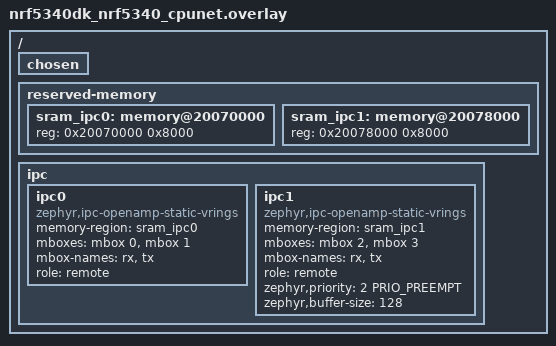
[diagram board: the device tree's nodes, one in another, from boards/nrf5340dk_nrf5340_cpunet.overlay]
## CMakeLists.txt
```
# Copyright 2026 NXP
# SPDX-License-Identifier: Apache-2.0

cmake_minimum_required(VERSION 3.20.0)

find_package(Zephyr REQUIRED HINTS $ENV{ZEPHYR_BASE})
project(mp_ipc_multi_core_remote)

target_sources(app PRIVATE src/main.c src/mp_test_sink.c)
target_sources_ifdef(CONFIG_MBOX app PRIVATE src/mbox_mock.c)
```

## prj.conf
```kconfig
# Copyright 2026 NXP
# SPDX-License-Identifier: Apache-2.0

CONFIG_MP=y
CONFIG_IPC_SERVICE=y
CONFIG_MP_PLUGIN_IPC=y

# IPC Service Backend Config
CONFIG_MBOX=y
CONFIG_OPENAMP=y
CONFIG_IPC_SERVICE_BACKEND_RPMSG=y
CONFIG_IPM=y
CONFIG_IPM_MHU=y

# Disable cache management for QEMU emulation to avoid arch-specific linker issues
CONFIG_CACHE_MANAGEMENT=n

# MediaPipe Subsystem Config
CONFIG_MP_THREADS_NUM=2
CONFIG_MP_NET_BUF_POOL_COUNT=8

# Logging Configuration
CONFIG_LOG=y
CONFIG_LOG_DEFAULT_LEVEL=3
CONFIG_MP_LOG_LEVEL_DBG=y
CONFIG_PRINTK=y

# Heap and buffer allocations
CONFIG_HEAP_MEM_POOL_SIZE=16384
CONFIG_NET_BUF=y
```

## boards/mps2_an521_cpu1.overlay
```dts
/*
 * Copyright 2026 NXP
 *
 * SPDX-License-Identifier: Apache-2.0
 */

/ {
	chosen {
		zephyr,ipc_shm = &sramx;
		zephyr,ipc = &mhu0;
	};

	sramx: memory@281f8000 {
		compatible = "mmio-sram";
		reg = <0x281f8000 0x8000>;
	};

	mbox_mock: mbox_mock {
		compatible = "zephyr,mbox-mock";
		#mbox-cells = <0>;
		status = "okay";
	};

	ipc0: ipc0 {
		compatible = "zephyr,ipc-openamp-static-vrings";
		memory-region = <&sramx>;
		mboxes = <&mbox_mock>, <&mbox_mock>;
		mbox-names = "tx", "rx";
		role = "remote";
		status = "okay";
	};
};
```

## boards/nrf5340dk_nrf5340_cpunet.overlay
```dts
/*
 * Copyright (c) 2021 Carlo Caione <ccaione@baylibre.com>
 *
 * SPDX-License-Identifier: Apache-2.0
 */

#include <zephyr/dt-bindings/ipc_service/static_vrings.h>

/delete-node/ &sram0_shared;

/ {
	chosen {
		/delete-property/ zephyr,ipc_shm;
	};

	reserved-memory {
		#address-cells = <1>;
		#size-cells = <1>;

		sram_ipc0: memory@20070000 {
			reg = <0x20070000 0x8000>;
		};

		sram_ipc1: memory@20078000 {
			reg = <0x20078000 0x8000>;
		};
	};

	ipc {
		/delete-node/ ipc0;

		ipc0: ipc0 {
			compatible = "zephyr,ipc-openamp-static-vrings";
			memory-region = <&sram_ipc0>;
			mboxes = <&mbox 0>, <&mbox 1>;
			mbox-names = "rx", "tx";
			role = "remote";
			status = "okay";
		};

		ipc1: ipc1 {
			compatible = "zephyr,ipc-openamp-static-vrings";
			memory-region = <&sram_ipc1>;
			mboxes = <&mbox 2>, <&mbox 3>;
			mbox-names = "rx", "tx";
			role = "remote";
			zephyr,priority = <2 PRIO_PREEMPT>;
			zephyr,buffer-size = <128>;
			status = "okay";
		};
	};
};
```

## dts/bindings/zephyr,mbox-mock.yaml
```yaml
description: Mock MBOX-to-IPM Shim

compatible: "zephyr,mbox-mock"

include: base.yaml

properties:
  "#mbox-cells":
    type: int
    const: 0
```

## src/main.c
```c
/*
 * Copyright (c) 2026 Qualcomm Innovation Center, Inc. All rights reserved.
 *
 * SPDX-License-Identifier: Apache-2.0
 */

#include <zephyr/kernel.h>
#include <zephyr/logging/log.h>
#include <zephyr/net_buf.h>

#include <zephyr/mp/core/mp.h>
#include <zephyr/mp/core/mp_pipeline.h>
#include <zephyr/mp/core/mp_bin.h>
#include <zephyr/mp/core/mp_element.h>
#include <zephyr/mp/core/mp_pad.h>
#include <zephyr/mp/ipc/mp_ipc.h>
#include <zephyr/mp/ipc/mp_ipc_protocol.h>

#include "mp_test_sink.h"

LOG_MODULE_REGISTER(mp_ipc_remote_app, LOG_LEVEL_INF);

#define PIPE_B_ID    0
#define IPC_SRC_ID   1
#define TEST_SINK_ID 2

static struct mp_pipeline pipeline_b;
static struct mp_ipc_src ipc_src;
static struct mp_test_sink test_sink;

/* Semaphore to signal from app_create_remote_pipeline() to main() */
K_SEM_DEFINE(pipeline_created_sem, 0, 1);

/* Application hook called from mp_ipc_src.c when CPU0 sends CREATE_PIPELINE */
int app_create_remote_pipeline(void)
{
	int ret;

	LOG_INF("[CPU1] Creating remote pipeline");

	/* Build the pipeline and elements */
	MP_ELEMENT_INIT(&pipeline_b, mp_pipeline_init, PIPE_B_ID);
	MP_ELEMENT_INIT(&test_sink, mp_test_sink_init, TEST_SINK_ID);

	ret = mp_element_link((struct mp_element *)&ipc_src, (struct mp_element *)&test_sink, NULL);
	if (ret < 0) {
		LOG_ERR("Failed to link ipc_src to test_sink (%d)", ret);
		return ret;
	}
	LOG_INF("[CPU1] Elements linked successfully.");

	ret = mp_bin_add((struct mp_bin *)&pipeline_b,
			 (struct mp_element *)&ipc_src,
			 (struct mp_element *)&test_sink,
			 NULL);
	if (ret < 0) {
		LOG_ERR("Failed to add elements to bin (%d)", ret);
		return ret;
	}
	LOG_INF("[CPU1] Elements added to bin successfully.");

	if (mp_element_set_state((struct mp_element *)&pipeline_b,
				 MP_STATE_PAUSED) != MP_STATE_CHANGE_SUCCESS) {
		LOG_ERR("Failed to pause receiver pipeline");
		return -EIO;
	}
	LOG_INF("[CPU1] Pipeline_b PAUSED state transition complete.");

	/* Notify main() that pipeline_b is now constructed */
	k_sem_give(&pipeline_created_sem);

	return 0;
}

int main(void)
{
	int ret;

	LOG_INF("Topology: ===== (IPC Service) =====> [ipc_src] -> [test_sink]");

	/* Initialize only ipc_src and register endpoint */
	LOG_INF("[CPU1] Initializing ipc_src endpoint");
	MP_ELEMENT_INIT(&ipc_src, mp_ipc_src_init, IPC_SRC_ID);

	if (mp_element_set_state((struct mp_element *)&ipc_src,
				 MP_STATE_PAUSED) != MP_STATE_CHANGE_SUCCESS) {
		LOG_ERR("Failed to pause ipc_src for endpoint registration");
		return -EIO;
	}

	LOG_INF("[CPU1] Waiting for CREATE_PIPELINE command from CPU0...");
	k_sem_take(&pipeline_created_sem, K_FOREVER);
	LOG_INF("[CPU1] Pipeline_b created; waiting for PLAYING and EOS / ERROR messages...");

	struct mp_bus *bus = mp_element_get_bus((struct mp_element *)&pipeline_b);
	struct mp_message msg;

	mp_bus_pop_msg(bus, MP_MESSAGE_ERROR | MP_MESSAGE_EOS, &msg);

	switch (msg.type) {
	case MP_MESSAGE_ERROR:
		LOG_ERR("ERROR message from element %d", msg.origin->object.id);
		break;
	case MP_MESSAGE_EOS:
		LOG_INF("EOS message from element %d (SUCCESS: Frame transfer completed)", msg.origin->object.id);
		break;
	default:
		LOG_ERR("Unexpected message from element %d", msg.origin->object.id);
		break;
	}

	/* Stop/Deinit pipeline */
	LOG_INF("Stopping pipeline...");
	(void)mp_element_set_state((struct mp_element *)&pipeline_b, MP_STATE_READY);

	LOG_INF("--- Remote Core Receiver Loop Finished ---");
	return 0;
}
```

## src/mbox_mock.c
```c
#include <zephyr/kernel.h>
#include <zephyr/device.h>
#include <zephyr/drivers/mbox.h>
#include <zephyr/drivers/ipm.h>

#define DT_DRV_COMPAT zephyr_mbox_mock

struct mbox_mock_data {
	const struct device *ipm_dev;
	mbox_callback_t cb;
	void *user_data;
};

static void ipm_callback_shim(const struct device *ipmdev, void *user_data, uint32_t id, volatile void *data)
{
	struct mbox_mock_data *drv_data = user_data;

	if (drv_data->cb) {
		drv_data->cb(NULL, 0, drv_data->user_data, NULL);
		drv_data->cb(NULL, 1, drv_data->user_data, NULL);
	}
}

static int mbox_mock_send(const struct device *dev, mbox_channel_id_t channel_id, const struct mbox_msg *msg)
{
	struct mbox_mock_data *drv_data = dev->data;

	if (!drv_data->ipm_dev) {
		drv_data->ipm_dev = DEVICE_DT_GET_OR_NULL(DT_CHOSEN(zephyr_ipc));
		if (!drv_data->ipm_dev) {
			return -ENODEV;
		}
	}

#if defined(CONFIG_BOARD_MPS2_AN521_CPU0)
	uint32_t target_cpu = 1; /* CPU1 */
#else
	uint32_t target_cpu = 0; /* CPU0 */
#endif

	return ipm_send(drv_data->ipm_dev, 0, target_cpu, NULL, 0);
}

static int mbox_mock_register_callback(const struct device *dev, mbox_channel_id_t channel_id, mbox_callback_t cb, void *user_data)
{
	struct mbox_mock_data *drv_data = dev->data;

	drv_data->cb = cb;
	drv_data->user_data = user_data;
	if (!drv_data->ipm_dev) {
		drv_data->ipm_dev = DEVICE_DT_GET_OR_NULL(DT_CHOSEN(zephyr_ipc));
		if (!drv_data->ipm_dev) {
			return -ENODEV;
		}
	}
	ipm_register_callback(drv_data->ipm_dev, ipm_callback_shim, drv_data);
	return 0;
}

static int mbox_mock_mtu_get(const struct device *dev)
{
	return 0;
}

static uint32_t mbox_mock_max_channels_get(const struct device *dev)
{
	return 2;
}

static int mbox_mock_set_enabled(const struct device *dev, mbox_channel_id_t channel_id, bool enabled)
{
	struct mbox_mock_data *drv_data = dev->data;

	if (!drv_data->ipm_dev) {
		drv_data->ipm_dev = DEVICE_DT_GET_OR_NULL(DT_CHOSEN(zephyr_ipc));
		if (!drv_data->ipm_dev) {
			return -ENODEV;
		}
	}
	return ipm_set_enabled(drv_data->ipm_dev, enabled ? 1 : 0);
}

static const struct mbox_driver_api mbox_mock_api = {
	.send = mbox_mock_send,
	.register_callback = mbox_mock_register_callback,
	.mtu_get = mbox_mock_mtu_get,
	.max_channels_get = mbox_mock_max_channels_get,
	.set_enabled = mbox_mock_set_enabled,
};

static int mbox_mock_init(const struct device *dev)
{
	return 0;
}

#define MBOX_MOCK_INIT(inst) \
	static struct mbox_mock_data mbox_mock_data_##inst; \
	DEVICE_DT_INST_DEFINE(inst, mbox_mock_init, NULL, &mbox_mock_data_##inst, NULL, \
			      POST_KERNEL, 2, &mbox_mock_api);

DT_INST_FOREACH_STATUS_OKAY(MBOX_MOCK_INIT)
```

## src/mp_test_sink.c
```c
/*
 * Copyright 2026 NXP
 *
 * SPDX-License-Identifier: Apache-2.0
 */

#include <zephyr/kernel.h>
#include <zephyr/logging/log.h>
#include <zephyr/net_buf.h>

#include <zephyr/mp/core/mp_bus.h>
#include <zephyr/mp/core/mp_message.h>
#include <zephyr/mp/core/mp_element.h>
#include <zephyr/mp/core/mp_caps.h>
#include <zephyr/mp/core/mp_dispatch.h>

#include "mp_test_sink.h"

LOG_MODULE_DECLARE(mp_ipc_remote_app, LOG_LEVEL_INF);

static int mp_test_sink_chainfn(struct mp_pad *pad, struct net_buf *buf, struct net_buf **out_buf)
{
	struct mp_test_sink *self = (struct mp_test_sink *)pad->object.container;
	struct mp_buffer_meta *meta = mp_buffer_get_meta(buf);

	self->frame_count++;
	LOG_INF("[Remote Core: mp_test_sink] Received Frame %d over Real IPC: size=%u, timestamp=%u", 
		self->frame_count, buf->len, meta->timestamp);

	/* When we receive 5 frames, post an EOS message to Pipeline B's bus */
	if (self->frame_count >= 5) {
		struct mp_bus *bus = mp_element_get_bus((struct mp_element *)self);
		if (bus) {
			struct mp_message eos_msg;
			MP_MESSAGE_INIT(&eos_msg, (struct mp_element *)self, MP_MESSAGE_EOS);
			mp_bus_post(bus, &eos_msg);
		}
	}

	/* Unreference/consume the received buffer to free it and signal release back to CPU0 */
	net_buf_unref(buf);

	if (out_buf) {
		*out_buf = NULL;
	}
	return 0;
}

static int mp_test_sink_queryfn(struct mp_pad *pad, struct mp_dispatch *query)
{
	if (query->type == MP_DISPATCH_CAPS) {
		struct mp_caps *caps = mp_caps_new_any();
		mp_dispatch_set_caps(query, caps);
		mp_caps_unref(caps);
		return 0;
	} else if (query->type == MP_DISPATCH_BUFFER_CONFIG) {
		return 0;
	}
	return -ENOTSUP;
}

void mp_test_sink_init(struct mp_element *self)
{
	struct mp_test_sink *tsink = (struct mp_test_sink *)self;
	mp_sink_init(self);
	tsink->base.sinkpad.chainfn = mp_test_sink_chainfn;
	tsink->base.sinkpad.queryfn = mp_test_sink_queryfn;
	tsink->frame_count = 0;
}
```

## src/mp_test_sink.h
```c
/*
 * Copyright 2026 NXP
 *
 * SPDX-License-Identifier: Apache-2.0
 */

#ifndef MP_TEST_SINK_H_
#define MP_TEST_SINK_H_

#include <zephyr/mp/core/mp_sink.h>

struct mp_test_sink {
	struct mp_sink base;
	int frame_count;
};

void mp_test_sink_init(struct mp_element *self);

#endif /* MP_TEST_SINK_H_ */
```
